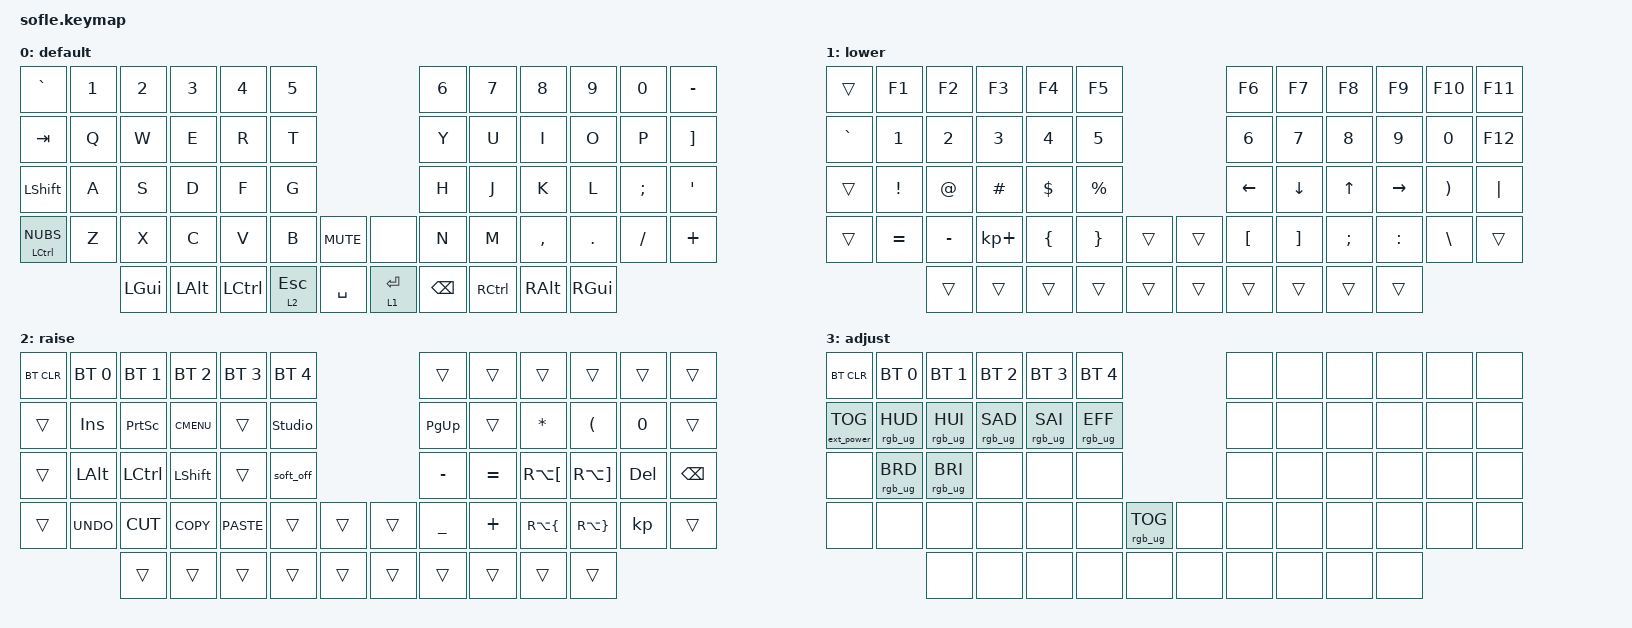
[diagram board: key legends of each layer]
/*
 * Copyright (c) 2020 The ZMK Contributors
 *
 * SPDX-License-Identifier: MIT
 */

#include <behaviors.dtsi>
#include <dt-bindings/zmk/bt.h>
#include <dt-bindings/zmk/ext_power.h>
#include <dt-bindings/zmk/keys.h>
#include <dt-bindings/zmk/rgb.h>

#define BASE 0
#define LOWER 1
#define RAISE 2
#define ADJUST 3

/ {
    // Activate ADJUST layer by pressing raise and lower

    behaviors {
        hml: homewrow_mods_left {
            compatible = "zmk,behavior-hold-tap";
            label = "homewrow_mods_left";
            bindings = <&kp>, <&kp>;

            #binding-cells = <2>;
            quick-tap-ms = <175>;
            tapping-term-ms = <200>;
            require-prior-idle-ms = <150>;
            hold-trigger-key-positions = <31 39 40 41 30 18 19 32 20 21 33 35 34 23 22 10 11 9 8 7 6>;
            flavor = "balanced";
            hold-trigger-on-release;             // delay positional check until key-release
        };

        hmr: homewrow_mods_right {
            compatible = "zmk,behavior-hold-tap";
            label = "HOMEROW_MODS_RIGHT_HAND";
            bindings = <&kp>, <&kp>;

            #binding-cells = <2>;
            quick-tap-ms = <175>;
            tapping-term-ms = <200>;
            require-prior-idle-ms = <150>;
            hold-trigger-key-positions = <38 0 1 2 3 4 5 12 13 14 15 16 17 24 25 26 27 28 29 36 37 38>;
            flavor = "balanced";
            hold-trigger-on-release;             // delay positional check until key-release
        };

        layers: layers {
            compatible = "zmk,behavior-hold-tap";
            label = "LAYERS";
            bindings = <&mo>, <&kp>;

            #binding-cells = <2>;
            tapping-term-ms = <200>;
            quick-tap-ms = <0>;
            require-prior-idle-ms = <0>;
            flavor = "balanced";
        };
    };

    conditional_layers {
        compatible = "zmk,conditional-layers";

        adjust_layer {
            if-layers = <LOWER RAISE>;
            then-layer = <ADJUST>;
        };
    };

    keymap {
        compatible = "zmk,keymap";

        default_layer {
            label = "default";

            // ------------------------------------------------------------------------------------------------------------
            // |   `   |  1  |  2  |  3   |  4   |  5   |                   |  6   |  7    |  8    |  9   |   0   |       |
            // |  ESC  |  Q  |  W  |  E   |  R   |  T   |                   |  Y   |  U    |  I    |  O   |   P   | BKSPC |
            // |  TAB  |  A  |  S  |  D   |  F   |  G   |                   |  H   |  J    |  K    |  L   |   ;   |   '   |
            // | SHIFT |  Z  |  X  |  C   |  V   |  B   |  MUTE  |  |       |  N   |  M    |  ,    |  .   |   /   | SHIFT |
            //               | GUI | ALT  | CTRL | LOWER|  ENTER |  | SPACE | RAISE| CTRL  | ALT   | GUI  |

            bindings = <
&kp GRAVE  &kp N1  &kp N2    &kp N3    &kp N4     &kp N5                              &kp N6     &kp N7     &kp N8     &kp N9    &kp N0    &kp MINUS 
&kp TAB &kp Q   &kp W     &kp E     &kp R      &kp T                               &kp Y      &kp U      &kp I      &kp O     &kp P     &kp RIGHT_BRACKET 
&kp LSHIFT &kp A   &kp S     &kp D     &kp F      &kp G                               &kp H      &kp J      &kp K      &kp L     &kp SEMI  &kp SQT
&mt LCTRL NUBS &kp Z   &kp X     &kp C     &kp V      &kp B      &kp C_MUTE    &none      &kp N      &kp M      &kp COMMA  &kp DOT   &kp FSLH  &kp PLUS 
                   &kp LGUI  &kp LALT  &kp LCTRL  &layers 2 ESCAPE &kp SPACE    &layers 1 ENTER  &kp BACKSPACE &kp RCTRL  &kp RALT   &kp RGUI
            >;

            sensor-bindings = <&inc_dec_kp C_VOL_UP C_VOL_DN &inc_dec_kp PG_UP PG_DN>;
        };

        lower_layer {
            label = "lower";

            // TODO: Some binds are waiting for shifted keycode support.
            // ------------------------------------------------------------------------------------------------------------
            // |       |  F1 |  F2 |  F3  |  F4  |  F5  |                   |  F6  |  F7   |  F8   |  F9  |  F10  |  F11  |
            // |   `   |  1  |  2  |  3   |  4   |  5   |                   |  6   |  7    |  8    |  9   |   0   |  F12  |
            // |       |  !  |  @  |  #   |  $   |  %   |                   |  ^   |  &    |  *    |  (   |   )   |   |   |
            // |       |  =  |  -  |  +   |  {   |  }   |        |  |       |  [   |  ]    |  ;    |  :   |   \   |       |
            //               |     |      |      |      |        |  |       |      |       |       |      |

            bindings = <
&trans     &kp F1     &kp F2     &kp F3       &kp F4    &kp F5                       &kp F6     &kp F7    &kp F8           &kp F9     &kp F10   &kp F11
&kp GRAVE  &kp N1     &kp N2     &kp N3       &kp N4    &kp N5                       &kp N6     &kp N7    &kp N8           &kp N9     &kp N0    &kp F12
&trans     &kp EXCL   &kp AT     &kp HASH     &kp DLLR  &kp PRCNT                    &kp LEFT   &kp DOWN  &kp UP           &kp RIGHT  &kp RPAR  &kp PIPE
&trans     &kp EQUAL  &kp MINUS  &kp KP_PLUS  &kp LBRC  &kp RBRC   &trans    &trans  &kp LBKT   &kp RBKT  &kp SEMI         &kp COLON  &kp BSLH  &trans
                      &trans     &trans       &trans    &trans     &trans    &trans  &trans     &trans    &trans           &trans
            >;

            sensor-bindings = <&inc_dec_kp C_VOL_UP C_VOL_DN &inc_dec_kp PG_UP PG_DN>;
        };

        raise_layer {
            label = "raise";

            // ------------------------------------------------------------------------------------------------------------
            // | BTCLR | BT1  | BT2  |  BT3  |  BT4  |  BT5 |                |      |      |       |      |       |       |
            // |       | INS  | PSCR | GUI   |       |      |                | PGUP |      |   ^   |      |       |       |
            // |       | ALT  | CTRL | SHIFT |       | CAPS |                | PGDN |   <- |   v   |  ->  |  DEL  | BKSPC |
            // |       | UNDO | CUT  | COPY  | PASTE |      |      |  |      |      |      |       |      |       |       |
            //                |      |       |       |      |      |  |      |      |      |       |      |

            bindings = <
&bt BT_CLR  &bt BT_SEL 0  &bt BT_SEL 1  &bt BT_SEL 2  &bt BT_SEL 3  &bt BT_SEL 4                    &trans     &trans    &trans    &trans     &trans   &trans
&trans      &kp INS       &kp PSCRN     &kp K_CMENU   &trans        &studio_unlock                          &kp PG_UP  &trans    &kp ASTERISK &kp LPAR     &kp N0   &trans
&trans      &kp LALT      &kp LCTRL     &kp LSHFT     &trans        &soft_off                        &kp MINUS  &kp EQUAL &kp RA(LBKT) &kp RA(RBKT)   &kp DEL  &kp BSPC
&trans      &kp K_UNDO    &kp K_CUT     &kp K_COPY    &kp K_PASTE   &trans        &trans    &trans  &kp UNDER  &kp PLUS    &kp RA(LBRC) &kp RA(RBRC)  &kp &trans
                          &trans        &trans        &trans        &trans        &trans    &trans  &trans     &trans    &trans    &trans
            >;

            sensor-bindings = <&inc_dec_kp C_VOL_UP C_VOL_DN &inc_dec_kp PG_UP PG_DN>;
        };

        adjust_layer {
            // ----------------------------------------------------------------------------------------------------------------------------
            // | BTCLR  |  BT1    |  BT2    |   BT3   |   BT4   |   BT5   |                  |      |      |       |      |       |       |
            // | EXTPWR | RGB_HUD | RGB_HUI | RGB_SAD | RGB_SAI | RGB_EFF |                  |      |      |       |      |       |       |
            // |        | RGB_BRD | RGB_BRI |         |         |         |                  |      |      |       |      |       |       |
            // |        |         |         |         |         |         | RGB_TOG | |      |      |      |       |      |       |       |
            //                    |         |         |         |         |         | |      |      |      |       |      |

            label = "adjust";
            bindings = <
&bt BT_CLR         &bt BT_SEL 0     &bt BT_SEL 1     &bt BT_SEL 2     &bt BT_SEL 3     &bt BT_SEL 4                               &none  &none  &none  &none  &none  &none
&ext_power EP_TOG  &rgb_ug RGB_HUD  &rgb_ug RGB_HUI  &rgb_ug RGB_SAD  &rgb_ug RGB_SAI  &rgb_ug RGB_EFF                            &none  &none  &none  &none  &none  &none
&none              &rgb_ug RGB_BRD  &rgb_ug RGB_BRI  &none            &none            &none                                      &none  &none  &none  &none  &none  &none
&none              &none            &none            &none            &none            &none            &rgb_ug RGB_TOG    &none  &none  &none  &none  &none  &none  &none
                                    &none            &none            &none            &none            &none              &none  &none  &none  &none  &none
            >;
        };
    };
};
